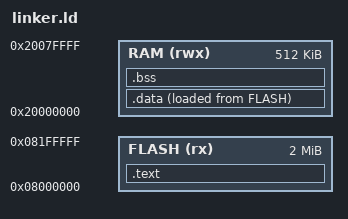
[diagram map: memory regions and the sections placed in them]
/* linker.ld - STM32F769I-DISCO */
ENTRY(Reset_Handler)

MEMORY
{
    FLASH (rx)  : ORIGIN = 0x08000000, LENGTH = 2048K
    RAM (rwx)   : ORIGIN = 0x20000000, LENGTH = 512K
}

_estack = ORIGIN(RAM) + LENGTH(RAM);

SECTIONS
{
    .text :
    {
        KEEP(*(.isr_vector))
        *(.text*)
        *(.rodata*)
        _etext = .;
    } > FLASH

    _sidata = LOADADDR(.data);

    .data :
    {
        _sdata = .;
        *(.data*)
        _edata = .;
    } > RAM AT > FLASH

    .bss :
    {
        _sbss = .;
        *(.bss*)
        *(COMMON)
        _ebss = .;
    } > RAM

    _end = .;
}
